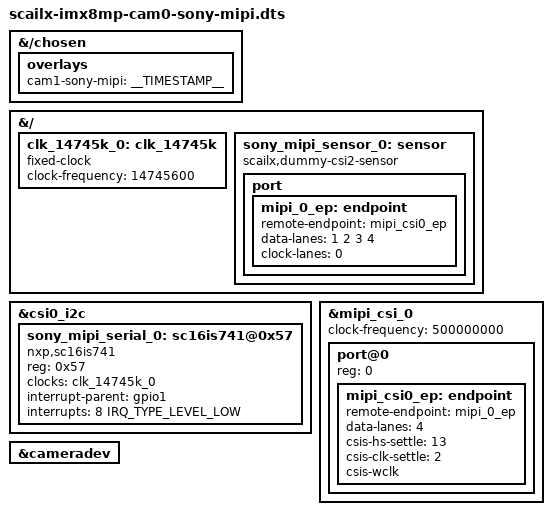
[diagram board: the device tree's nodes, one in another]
// SPDX-License-Identifier: (GPL-2.0 OR MIT)
/*
 * Copyright (C) 2024 VideologyInc
 *
 */

/dts-v1/;
/plugin/;

#include "imx8mp-pinfunc.h"
#include <dt-bindings/clock/imx8mp-clock.h>
#include <dt-bindings/interrupt-controller/arm-gic.h>

&{/chosen} {
	overlays {
		cam1-sony-mipi = __TIMESTAMP__;
	};
};

&{/} {
	clk_14745k_0: clk_14745k {
		compatible = "fixed-clock";
		#clock-cells = <0>;
		clock-frequency = <14745600>;
	};

	sony_mipi_sensor_0: sensor {
		compatible = "scailx,dummy-csi2-sensor";
		status = "okay";

		port {
			mipi_0_ep: endpoint {
				remote-endpoint = <&mipi_csi0_ep>;
				data-lanes = <1 2 3 4>;
				clock-lanes = <0>;
			};
		};
	};
};

&csi0_i2c {
	#address-cells = <1>;
	#size-cells = <0>;
	sony_mipi_serial_0: sc16is741@0x57 {
		compatible = "nxp,sc16is741";
		reg = <0x57>;
		clocks = <&clk_14745k_0>;
		interrupt-parent = <&gpio1>;
		interrupts = <8 IRQ_TYPE_LEVEL_LOW>;
		// gpio-controller;
		// #gpio-cells = <2>;
	};
};


&mipi_csi_0 {
	#address-cells = <1>;
	#size-cells = <0>;
	clock-frequency = <500000000>;
	status = "okay";

	port@0 {
		reg = <0>;
		mipi_csi0_ep: endpoint {
			remote-endpoint = <&mipi_0_ep>;
			data-lanes = <4>;
			csis-hs-settle = <13>;
			csis-clk-settle = <2>;
			csis-wclk;
		};
	};
};

&cameradev {
status = "okay";
};
